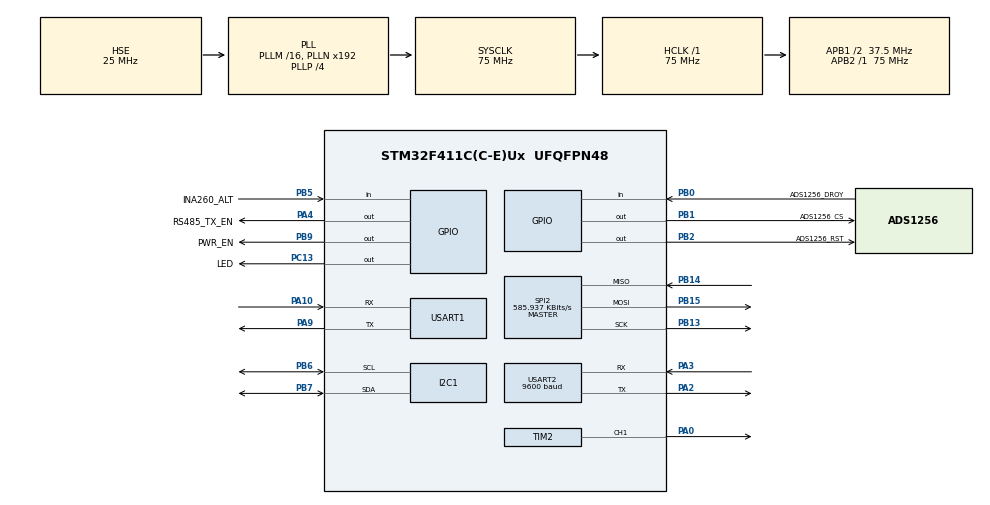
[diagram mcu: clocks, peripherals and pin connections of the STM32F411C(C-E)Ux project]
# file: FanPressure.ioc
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Dma.Request0=USART1_RX
Dma.Request1=USART2_RX
Dma.USART1_RX.0.Direction=DMA_PERIPH_TO_MEMORY
Dma.USART1_RX.0.FIFOMode=DMA_FIFOMODE_DISABLE
Dma.USART1_RX.0.Instance=DMA2_Stream2
Dma.USART1_RX.0.MemDataAlignment=DMA_MDATAALIGN_BYTE
Dma.USART1_RX.0.MemInc=DMA_MINC_ENABLE
Dma.USART1_RX.0.Mode=DMA_NORMAL
Dma.USART1_RX.0.PeriphDataAlignment=DMA_PDATAALIGN_BYTE
Dma.USART1_RX.0.PeriphInc=DMA_PINC_DISABLE
Dma.USART1_RX.0.Priority=DMA_PRIORITY_LOW
Dma.USART2_RX.1.Direction=DMA_PERIPH_TO_MEMORY
Dma.USART2_RX.1.FIFOMode=DMA_FIFOMODE_DISABLE
Dma.USART2_RX.1.Instance=DMA1_Stream5
Dma.USART2_RX.1.MemDataAlignment=DMA_MDATAALIGN_BYTE
Dma.USART2_RX.1.MemInc=DMA_MINC_ENABLE
Dma.USART2_RX.1.Mode=DMA_NORMAL
Dma.USART2_RX.1.PeriphDataAlignment=DMA_PDATAALIGN_BYTE
Dma.USART2_RX.1.PeriphInc=DMA_PINC_DISABLE
Dma.USART2_RX.1.Priority=DMA_PRIORITY_LOW
Mcu.Family=STM32F4
Mcu.Name=STM32F411C(C-E)Ux
Mcu.Package=UFQFPN48
NVIC.DMA1_Stream5_IRQn=true\:0\:0\:false\:false\:true\:false\:true\:true
NVIC.DMA2_Stream2_IRQn=true\:0\:0\:false\:false\:true\:false\:true\:true
NVIC.PriorityGroup=NVIC_PRIORITYGROUP_4
NVIC.TIM1_BRK_TIM9_IRQn=true\:0\:0\:false\:false\:true\:true\:true\:true
NVIC.USART1_IRQn=true\:0\:0\:false\:false\:true\:true\:true\:true
NVIC.USART2_IRQn=true\:0\:0\:false\:false\:true\:true\:true\:true
PA0-WKUP.Signal=S_TIM2_CH1_ETR
PA10.Mode=Asynchronous
PA10.Signal=USART1_RX
PA13.Mode=Serial_Wire
PA13.Signal=SYS_JTMS-SWDIO
PA14.Mode=Serial_Wire
PA14.Signal=SYS_JTCK-SWCLK
PA2.Mode=Asynchronous
PA2.Signal=USART2_TX
PA3.Mode=Asynchronous
PA3.Signal=USART2_RX
PA4.GPIO_Label=RS485_TX_EN
PA4.Signal=GPIO_Output
PA9.Mode=Asynchronous
PA9.Signal=USART1_TX
PB0.GPIO_Label=ADS1256_DROY
PB0.Signal=GPIO_Input
PB1.GPIO_Label=ADS1256_CS
PB1.Signal=GPIO_Output
PB13.Mode=Full_Duplex_Master
PB13.Signal=SPI2_SCK
PB14.Mode=Full_Duplex_Master
PB14.Signal=SPI2_MISO
PB15.Mode=Full_Duplex_Master
PB15.Signal=SPI2_MOSI
PB2.GPIO_Label=ADS1256_RST
PB2.Signal=GPIO_Output
PB5.GPIO_Label=INA260_ALT
PB5.Signal=GPIO_Input
PB6.Mode=I2C
PB6.Signal=I2C1_SCL
PB7.Mode=I2C
PB7.Signal=I2C1_SDA
PB9.GPIO_Label=PWR_EN
PB9.Signal=GPIO_Output
PC13-ANTI_TAMP.GPIO_Label=LED
PC13-ANTI_TAMP.Signal=GPIO_Output
PC14-OSC32_IN.Mode=LSE-External-Oscillator
PC14-OSC32_IN.Signal=RCC_OSC32_IN
PC15-OSC32_OUT.Mode=LSE-External-Oscillator
PC15-OSC32_OUT.Signal=RCC_OSC32_OUT
PH0\ -\ OSC_IN.Mode=HSE-External-Oscillator
PH0\ -\ OSC_IN.Signal=RCC_OSC_IN
PH1\ -\ OSC_OUT.Mode=HSE-External-Oscillator
PH1\ -\ OSC_OUT.Signal=RCC_OSC_OUT
ProjectManager.HeapSize=0x200
ProjectManager.StackSize=0x400
ProjectManager.TargetToolchain=STM32CubeIDE
RCC.48MHZClocksFreq_Value=75000000
RCC.AHBFreq_Value=75000000
RCC.APB1CLKDivider=RCC_HCLK_DIV2
RCC.APB1Freq_Value=37500000
RCC.APB1TimFreq_Value=75000000
RCC.APB2Freq_Value=75000000
RCC.APB2TimFreq_Value=75000000
RCC.CortexFreq_Value=75000000
RCC.HCLKFreq_Value=75000000
RCC.HSE_VALUE=25000000
RCC.HSI_VALUE=16000000
RCC.PLLP=RCC_PLLP_DIV4
RCC.PLLSourceVirtual=RCC_PLLSOURCE_HSE
RCC.SYSCLKFreq_VALUE=75000000
RCC.SYSCLKSource=RCC_SYSCLKSOURCE_PLLCLK
RCC.VCOOutputFreq_Value=300000000
SH.S_TIM2_CH1_ETR.0=TIM2_CH1,PWM Generation1 CH1
SPI2.BaudRatePrescaler=SPI_BAUDRATEPRESCALER_64
SPI2.CLKPhase=SPI_PHASE_2EDGE
SPI2.CLKPolarity=SPI_POLARITY_LOW
SPI2.CalculateBaudRate=585.937 KBits/s
SPI2.Direction=SPI_DIRECTION_2LINES
SPI2.Mode=SPI_MODE_MASTER
SPI2.VirtualType=VM_MASTER
TIM1.Period=10000
TIM1.Prescaler=7499
TIM2.AutoReloadPreload=TIM_AUTORELOAD_PRELOAD_ENABLE
TIM2.Channel-PWM\ Generation1\ CH1=TIM_CHANNEL_1
TIM2.Period=999
TIM2.Prescaler=74
USART1.VirtualMode=VM_ASYNC
USART2.BaudRate=9600
USART2.VirtualMode=VM_ASYNC
VP_TIM1_VS_ClockSourceINT.Mode=Internal
VP_TIM2_VS_ClockSourceINT.Mode=Internal
board=custom

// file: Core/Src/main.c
/* USER CODE BEGIN Header */
/**
  ******************************************************************************
  * @file           : main.c
  * @brief          : Main program body
  ******************************************************************************
  * @attention
  *
  * Copyright (c) 2024 STMicroelectronics.
  * All rights reserved.
  *
  * This software is licensed under terms that can be found in the LICENSE file
  * in the root directory of this software component.
  * If no LICENSE file comes with this software, it is provided AS-IS.
  *
  ******************************************************************************
  */
/* USER CODE END Header */
#include "main.h"

/* USER CODE BEGIN Includes */
//#include "INA219h.h"
//#include "Ina219.h"
#include "mainpp.h"
/* USER CODE END Includes */

I2C_HandleTypeDef hi2c1;

SPI_HandleTypeDef hspi2;

TIM_HandleTypeDef htim1;
TIM_HandleTypeDef htim2;

UART_HandleTypeDef huart1;
UART_HandleTypeDef huart2;
DMA_HandleTypeDef hdma_usart1_rx;
DMA_HandleTypeDef hdma_usart2_rx;

void SystemClock_Config(void);
static void MX_GPIO_Init(void);
static void MX_DMA_Init(void);
static void MX_I2C1_Init(void);
static void MX_USART1_UART_Init(void);
static void MX_USART2_UART_Init(void);
static void MX_SPI2_Init(void);
static void MX_TIM2_Init(void);
static void MX_TIM1_Init(void);
/* USER CODE BEGIN PFP */

#ifdef __GNUC__
#define PUTCHAR_PROTOTYPE int __io_putchar(int ch)
#else
#define PUTCHAR_PROTOTYPE int fputc(int ch, FILE *f)
#endif

/* USER CODE END PFP */

/* USER CODE BEGIN 0 */
PUTCHAR_PROTOTYPE
{
  HAL_UART_Transmit(&huart1, (uint8_t *)&ch, 1, HAL_MAX_DELAY);
  return ch;
}

/* USER CODE END 0 */

int main(void)
{

  /* MCU Configuration--------------------------------------------------------*/

  /* Reset of all peripherals, Initializes the Flash interface and the Systick. */
  HAL_Init();

  /* Configure the system clock */
  SystemClock_Config();

  /* Initialize all configured peripherals */
  MX_GPIO_Init();
  MX_DMA_Init();
  MX_I2C1_Init();
  MX_USART1_UART_Init();
  MX_USART2_UART_Init();
  MX_SPI2_Init();
  MX_TIM2_Init();
  MX_TIM1_Init();
  /* USER CODE BEGIN 2 */
  setup();
  /*
  for(uint8_t i=1; i<128; i++)
  {
	  auto ret = HAL_I2C_IsDeviceReady(&hi2c1, (uint16_t)(i<<1), 3, 5);
	  if (ret == HAL_OK)
	  {
		  printf("Find INA I2C, Address: %u\n",i);
	  }
  }*/
  //HAL_GPIO_WritePin(LED_GPIO_Port, LED_Pin, GPIO_PIN_RESET);

  /*while(!(&ina219, &hi2c1, INA219_ADDRESS))
  {
	  printf("Initialize Ina219 Failed,Try Again...\n");
	  HAL_Delay(200);
  }*/
  //printf("Initialize Ina219 Successfully\n");

  //INA219_setCalibration_32V_1A(&ina219);

  //HAL_GPIO_WritePin(LED_GPIO_Port, LED_Pin, GPIO_PIN_SET);

  /* USER CODE END 2 */

  /* Infinite loop */
  /* USER CODE BEGIN WHILE */
  while (1)
  {
	  loop();
	  /*HAL_GPIO_TogglePin(LED_GPIO_Port, LED_Pin);

	  auto vbus = hina219.getBusVoltage();
	  auto vshunt = hina219.getCurrent();
	  auto current = hina219.getShuntVoltage();

	  printf("voltage: %f\t Shunt voltage: %f\t current: %f\n",vbus,vshunt,current);

	  HAL_Delay(500);*/
    /* USER CODE END WHILE */

  }
}

void SystemClock_Config(void)
{
  RCC_OscInitTypeDef RCC_OscInitStruct = {0};
  RCC_ClkInitTypeDef RCC_ClkInitStruct = {0};

  /** Configure the main internal regulator output voltage
  */
  __HAL_RCC_PWR_CLK_ENABLE();
  __HAL_PWR_VOLTAGESCALING_CONFIG(PWR_REGULATOR_VOLTAGE_SCALE1);

  /** Initializes the RCC Oscillators according to the specified parameters
  * in the RCC_OscInitTypeDef structure.
  */
  RCC_OscInitStruct.OscillatorType = RCC_OSCILLATORTYPE_HSE;
  RCC_OscInitStruct.HSEState = RCC_HSE_ON;
  RCC_OscInitStruct.PLL.PLLState = RCC_PLL_ON;
  RCC_OscInitStruct.PLL.PLLSource = RCC_PLLSOURCE_HSE;
  RCC_OscInitStruct.PLL.PLLM = 16;
  RCC_OscInitStruct.PLL.PLLN = 192;
  RCC_OscInitStruct.PLL.PLLP = RCC_PLLP_DIV4;
  RCC_OscInitStruct.PLL.PLLQ = 4;
  if (HAL_RCC_OscConfig(&RCC_OscInitStruct) != HAL_OK)
  {
    Error_Handler();
  }

  /** Initializes the CPU, AHB and APB buses clocks
  */
  RCC_ClkInitStruct.ClockType = RCC_CLOCKTYPE_HCLK|RCC_CLOCKTYPE_SYSCLK
                              |RCC_CLOCKTYPE_PCLK1|RCC_CLOCKTYPE_PCLK2;
  RCC_ClkInitStruct.SYSCLKSource = RCC_SYSCLKSOURCE_PLLCLK;
  RCC_ClkInitStruct.AHBCLKDivider = RCC_SYSCLK_DIV1;
  RCC_ClkInitStruct.APB1CLKDivider = RCC_HCLK_DIV2;
  RCC_ClkInitStruct.APB2CLKDivider = RCC_HCLK_DIV1;

  if (HAL_RCC_ClockConfig(&RCC_ClkInitStruct, FLASH_LATENCY_2) != HAL_OK)
  {
    Error_Handler();
  }
}

static void MX_I2C1_Init(void)
{

  hi2c1.Instance = I2C1;
  hi2c1.Init.ClockSpeed = 100000;
  hi2c1.Init.DutyCycle = I2C_DUTYCYCLE_2;
  hi2c1.Init.OwnAddress1 = 0;
  hi2c1.Init.AddressingMode = I2C_ADDRESSINGMODE_7BIT;
  hi2c1.Init.DualAddressMode = I2C_DUALADDRESS_DISABLE;
  hi2c1.Init.OwnAddress2 = 0;
  hi2c1.Init.GeneralCallMode = I2C_GENERALCALL_DISABLE;
  hi2c1.Init.NoStretchMode = I2C_NOSTRETCH_DISABLE;
  if (HAL_I2C_Init(&hi2c1) != HAL_OK)
  {
    Error_Handler();
  }

}

static void MX_SPI2_Init(void)
{

  /* SPI2 parameter configuration*/
  hspi2.Instance = SPI2;
  hspi2.Init.Mode = SPI_MODE_MASTER;
  hspi2.Init.Direction = SPI_DIRECTION_2LINES;
  hspi2.Init.DataSize = SPI_DATASIZE_8BIT;
  hspi2.Init.CLKPolarity = SPI_POLARITY_LOW;
  hspi2.Init.CLKPhase = SPI_PHASE_2EDGE;
  hspi2.Init.NSS = SPI_NSS_SOFT;
  hspi2.Init.BaudRatePrescaler = SPI_BAUDRATEPRESCALER_64;
  hspi2.Init.FirstBit = SPI_FIRSTBIT_MSB;
  hspi2.Init.TIMode = SPI_TIMODE_DISABLE;
  hspi2.Init.CRCCalculation = SPI_CRCCALCULATION_DISABLE;
  hspi2.Init.CRCPolynomial = 10;
  if (HAL_SPI_Init(&hspi2) != HAL_OK)
  {
    Error_Handler();
  }

}

static void MX_TIM1_Init(void)
{

  TIM_ClockConfigTypeDef sClockSourceConfig = {0};
  TIM_MasterConfigTypeDef sMasterConfig = {0};

  htim1.Instance = TIM1;
  htim1.Init.Prescaler = 7499;
  htim1.Init.CounterMode = TIM_COUNTERMODE_UP;
  htim1.Init.Period = 10000;
  htim1.Init.ClockDivision = TIM_CLOCKDIVISION_DIV1;
  htim1.Init.RepetitionCounter = 0;
  htim1.Init.AutoReloadPreload = TIM_AUTORELOAD_PRELOAD_DISABLE;
  if (HAL_TIM_Base_Init(&htim1) != HAL_OK)
  {
    Error_Handler();
  }
  sClockSourceConfig.ClockSource = TIM_CLOCKSOURCE_INTERNAL;
  if (HAL_TIM_ConfigClockSource(&htim1, &sClockSourceConfig) != HAL_OK)
  {
    Error_Handler();
  }
  sMasterConfig.MasterOutputTrigger = TIM_TRGO_RESET;
  sMasterConfig.MasterSlaveMode = TIM_MASTERSLAVEMODE_DISABLE;
  if (HAL_TIMEx_MasterConfigSynchronization(&htim1, &sMasterConfig) != HAL_OK)
  {
    Error_Handler();
  }

}

static void MX_TIM2_Init(void)
{

  TIM_ClockConfigTypeDef sClockSourceConfig = {0};
  TIM_MasterConfigTypeDef sMasterConfig = {0};
  TIM_OC_InitTypeDef sConfigOC = {0};

  htim2.Instance = TIM2;
  htim2.Init.Prescaler = 74;
  htim2.Init.CounterMode = TIM_COUNTERMODE_UP;
  htim2.Init.Period = 999;
  htim2.Init.ClockDivision = TIM_CLOCKDIVISION_DIV1;
  htim2.Init.AutoReloadPreload = TIM_AUTORELOAD_PRELOAD_ENABLE;
  if (HAL_TIM_Base_Init(&htim2) != HAL_OK)
  {
    Error_Handler();
  }
  sClockSourceConfig.ClockSource = TIM_CLOCKSOURCE_INTERNAL;
  if (HAL_TIM_ConfigClockSource(&htim2, &sClockSourceConfig) != HAL_OK)
  {
    Error_Handler();
  }
  if (HAL_TIM_PWM_Init(&htim2) != HAL_OK)
  {
    Error_Handler();
  }
  sMasterConfig.MasterOutputTrigger = TIM_TRGO_RESET;
  sMasterConfig.MasterSlaveMode = TIM_MASTERSLAVEMODE_DISABLE;
  if (HAL_TIMEx_MasterConfigSynchronization(&htim2, &sMasterConfig) != HAL_OK)
  {
    Error_Handler();
  }
  sConfigOC.OCMode = TIM_OCMODE_PWM1;
  sConfigOC.Pulse = 0;
  sConfigOC.OCPolarity = TIM_OCPOLARITY_HIGH;
  sConfigOC.OCFastMode = TIM_OCFAST_DISABLE;
  if (HAL_TIM_PWM_ConfigChannel(&htim2, &sConfigOC, TIM_CHANNEL_1) != HAL_OK)
  {
    Error_Handler();
  }
  HAL_TIM_MspPostInit(&htim2);

}

static void MX_USART1_UART_Init(void)
{

  huart1.Instance = USART1;
  huart1.Init.BaudRate = 115200;
  huart1.Init.WordLength = UART_WORDLENGTH_8B;
  huart1.Init.StopBits = UART_STOPBITS_1;
  huart1.Init.Parity = UART_PARITY_NONE;
  huart1.Init.Mode = UART_MODE_TX_RX;
  huart1.Init.HwFlowCtl = UART_HWCONTROL_NONE;
  huart1.Init.OverSampling = UART_OVERSAMPLING_16;
  if (HAL_UART_Init(&huart1) != HAL_OK)
  {
    Error_Handler();
  }

}

static void MX_USART2_UART_Init(void)
{

  huart2.Instance = USART2;
  huart2.Init.BaudRate = 9600;
  huart2.Init.WordLength = UART_WORDLENGTH_8B;
  huart2.Init.StopBits = UART_STOPBITS_1;
  huart2.Init.Parity = UART_PARITY_NONE;
  huart2.Init.Mode = UART_MODE_TX_RX;
  huart2.Init.HwFlowCtl = UART_HWCONTROL_NONE;
  huart2.Init.OverSampling = UART_OVERSAMPLING_16;
  if (HAL_UART_Init(&huart2) != HAL_OK)
  {
    Error_Handler();
  }

}

static void MX_DMA_Init(void)
{

  /* DMA controller clock enable */
  __HAL_RCC_DMA2_CLK_ENABLE();
  __HAL_RCC_DMA1_CLK_ENABLE();

  /* DMA interrupt init */
  /* DMA1_Stream5_IRQn interrupt configuration */
  HAL_NVIC_SetPriority(DMA1_Stream5_IRQn, 0, 0);
  HAL_NVIC_EnableIRQ(DMA1_Stream5_IRQn);
  /* DMA2_Stream2_IRQn interrupt configuration */
  HAL_NVIC_SetPriority(DMA2_Stream2_IRQn, 0, 0);
  HAL_NVIC_EnableIRQ(DMA2_Stream2_IRQn);

}

static void MX_GPIO_Init(void)
{
  GPIO_InitTypeDef GPIO_InitStruct = {0};

  /* GPIO Ports Clock Enable */
  __HAL_RCC_GPIOC_CLK_ENABLE();
  __HAL_RCC_GPIOH_CLK_ENABLE();
  __HAL_RCC_GPIOA_CLK_ENABLE();
  __HAL_RCC_GPIOB_CLK_ENABLE();

  /*Configure GPIO pin Output Level */
  HAL_GPIO_WritePin(LED_GPIO_Port, LED_Pin, GPIO_PIN_RESET);

  /*Configure GPIO pin Output Level */
  HAL_GPIO_WritePin(RS485_TX_EN_GPIO_Port, RS485_TX_EN_Pin, GPIO_PIN_RESET);

  /*Configure GPIO pin Output Level */
  HAL_GPIO_WritePin(GPIOB, ADS1256_CS_Pin|ADS1256_RST_Pin|PWR_EN_Pin, GPIO_PIN_RESET);

  /*Configure GPIO pin : LED_Pin */
  GPIO_InitStruct.Pin = LED_Pin;
  GPIO_InitStruct.Mode = GPIO_MODE_OUTPUT_PP;
  GPIO_InitStruct.Pull = GPIO_NOPULL;
  GPIO_InitStruct.Speed = GPIO_SPEED_FREQ_LOW;
  HAL_GPIO_Init(LED_GPIO_Port, &GPIO_InitStruct);

  /*Configure GPIO pin : RS485_TX_EN_Pin */
  GPIO_InitStruct.Pin = RS485_TX_EN_Pin;
  GPIO_InitStruct.Mode = GPIO_MODE_OUTPUT_PP;
  GPIO_InitStruct.Pull = GPIO_NOPULL;
  GPIO_InitStruct.Speed = GPIO_SPEED_FREQ_LOW;
  HAL_GPIO_Init(RS485_TX_EN_GPIO_Port, &GPIO_InitStruct);

  /*Configure GPIO pins : ADS1256_DROY_Pin INA260_ALT_Pin */
  GPIO_InitStruct.Pin = ADS1256_DROY_Pin|INA260_ALT_Pin;
  GPIO_InitStruct.Mode = GPIO_MODE_INPUT;
  GPIO_InitStruct.Pull = GPIO_NOPULL;
  HAL_GPIO_Init(GPIOB, &GPIO_InitStruct);

  /*Configure GPIO pins : ADS1256_CS_Pin ADS1256_RST_Pin PWR_EN_Pin */
  GPIO_InitStruct.Pin = ADS1256_CS_Pin|ADS1256_RST_Pin|PWR_EN_Pin;
  GPIO_InitStruct.Mode = GPIO_MODE_OUTPUT_PP;
  GPIO_InitStruct.Pull = GPIO_NOPULL;
  GPIO_InitStruct.Speed = GPIO_SPEED_FREQ_LOW;
  HAL_GPIO_Init(GPIOB, &GPIO_InitStruct);

}

void Error_Handler(void)
{
  __disable_irq();
  while (1)
  {
  }
}
